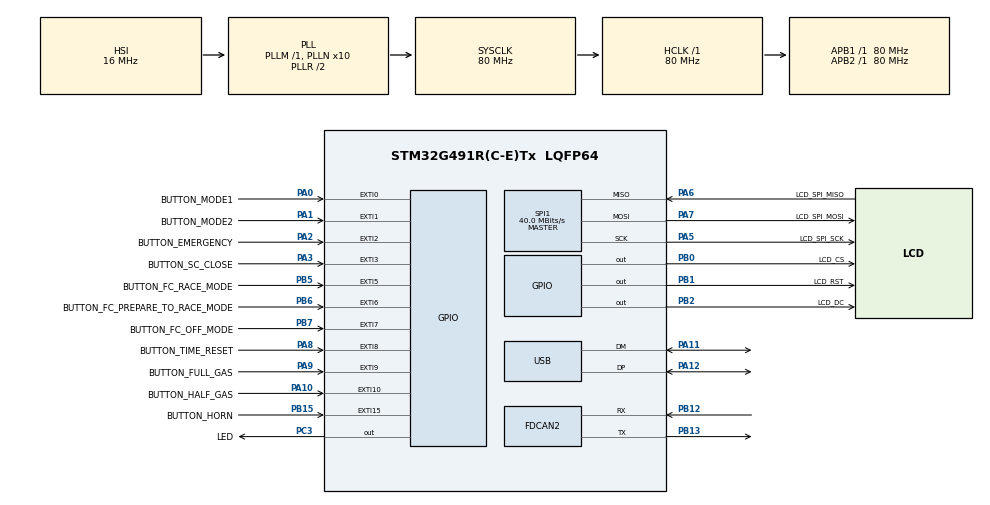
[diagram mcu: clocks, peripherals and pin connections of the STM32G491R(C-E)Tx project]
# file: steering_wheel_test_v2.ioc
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Dma.Request0=SPI1_TX
Dma.SPI1_TX.0.Direction=DMA_MEMORY_TO_PERIPH
Dma.SPI1_TX.0.EventEnable=DISABLE
Dma.SPI1_TX.0.Instance=DMA1_Channel3
Dma.SPI1_TX.0.MemDataAlignment=DMA_MDATAALIGN_BYTE
Dma.SPI1_TX.0.MemInc=DMA_MINC_ENABLE
Dma.SPI1_TX.0.Mode=DMA_NORMAL
Dma.SPI1_TX.0.PeriphDataAlignment=DMA_PDATAALIGN_BYTE
Dma.SPI1_TX.0.PeriphInc=DMA_PINC_DISABLE
Dma.SPI1_TX.0.Polarity=HAL_DMAMUX_REQ_GEN_RISING
Dma.SPI1_TX.0.Priority=DMA_PRIORITY_LOW
Dma.SPI1_TX.0.RequestNumber=1
Dma.SPI1_TX.0.SignalID=NONE
Dma.SPI1_TX.0.SyncEnable=DISABLE
Dma.SPI1_TX.0.SyncPolarity=HAL_DMAMUX_SYNC_NO_EVENT
Dma.SPI1_TX.0.SyncRequestNumber=1
Dma.SPI1_TX.0.SyncSignalID=NONE
FDCAN2.AutoRetransmission=ENABLE
FDCAN2.CalculateBaudRateNominal=500000
FDCAN2.CalculateTimeBitNominal=2000
FDCAN2.CalculateTimeQuantumNominal=400.0
FDCAN2.NominalPrescaler=32
FDCAN2.StdFiltersNbr=3
Mcu.Family=STM32G4
Mcu.Name=STM32G491R(C-E)Tx
Mcu.Package=LQFP64
NVIC.DMA1_Channel3_IRQn=true\:0\:0\:false\:false\:true\:false\:true\:true
NVIC.EXTI0_IRQn=true\:0\:0\:false\:false\:true\:true\:true\:true
NVIC.EXTI15_10_IRQn=true\:0\:0\:false\:false\:true\:true\:true\:true
NVIC.EXTI1_IRQn=true\:0\:0\:false\:false\:true\:true\:true\:true
NVIC.EXTI2_IRQn=true\:0\:0\:false\:false\:true\:true\:true\:true
NVIC.EXTI3_IRQn=true\:0\:0\:false\:false\:true\:true\:true\:true
NVIC.EXTI9_5_IRQn=true\:0\:0\:false\:false\:true\:true\:true\:true
NVIC.PriorityGroup=NVIC_PRIORITYGROUP_4
NVIC.SPI1_IRQn=true\:0\:0\:false\:false\:true\:true\:true\:true
NVIC.TIM6_DAC_IRQn=true\:0\:0\:false\:false\:true\:true\:true\:true
PA0.GPIO_Label=BUTTON_MODE1
PA0.GPIO_ModeDefaultEXTI=GPIO_MODE_IT_RISING_FALLING
PA0.GPIO_PuPd=GPIO_PULLUP
PA0.Signal=GPXTI0
PA1.GPIO_Label=BUTTON_MODE2
PA1.GPIO_ModeDefaultEXTI=GPIO_MODE_IT_RISING_FALLING
PA1.GPIO_PuPd=GPIO_PULLUP
PA1.Signal=GPXTI1
PA10.GPIO_Label=BUTTON_HALF_GAS
PA10.GPIO_ModeDefaultEXTI=GPIO_MODE_IT_RISING_FALLING
PA10.GPIO_PuPd=GPIO_PULLUP
PA10.Signal=GPXTI10
PA11.Mode=Device
PA11.Signal=USB_DM
PA12.Mode=Device
PA12.Signal=USB_DP
PA13.GPIO_Label=T_SWDIO
PA13.Mode=Trace_Asynchronous_SW
PA13.Signal=SYS_JTMS-SWDIO
PA14.GPIO_Label=T_SWCLK
PA14.Mode=Trace_Asynchronous_SW
PA14.Signal=SYS_JTCK-SWCLK
PA2.GPIO_Label=BUTTON_EMERGENCY
PA2.GPIO_ModeDefaultEXTI=GPIO_MODE_IT_RISING_FALLING
PA2.GPIO_PuPd=GPIO_PULLUP
PA2.Signal=GPXTI2
PA3.GPIO_Label=BUTTON_SC_CLOSE
PA3.GPIO_ModeDefaultEXTI=GPIO_MODE_IT_RISING_FALLING
PA3.GPIO_PuPd=GPIO_PULLUP
PA3.Signal=GPXTI3
PA5.GPIO_Label=LCD_SPI_SCK
PA5.GPIO_Speed=GPIO_SPEED_FREQ_VERY_HIGH
PA5.Mode=Full_Duplex_Master
PA5.Signal=SPI1_SCK
PA6.GPIO_Label=LCD_SPI_MISO
PA6.GPIO_Speed=GPIO_SPEED_FREQ_VERY_HIGH
PA6.Mode=Full_Duplex_Master
PA6.Signal=SPI1_MISO
PA7.GPIO_Label=LCD_SPI_MOSI
PA7.GPIO_Speed=GPIO_SPEED_FREQ_VERY_HIGH
PA7.Mode=Full_Duplex_Master
PA7.Signal=SPI1_MOSI
PA8.GPIO_Label=BUTTON_TIME_RESET
PA8.GPIO_ModeDefaultEXTI=GPIO_MODE_IT_RISING_FALLING
PA8.GPIO_PuPd=GPIO_PULLUP
PA8.Signal=GPXTI8
PA9.GPIO_Label=BUTTON_FULL_GAS
PA9.GPIO_ModeDefaultEXTI=GPIO_MODE_IT_RISING_FALLING
PA9.GPIO_PuPd=GPIO_PULLUP
PA9.Signal=GPXTI9
PB0.GPIO_Label=LCD_CS
PB0.Signal=GPIO_Output
PB1.GPIO_Label=LCD_RST
PB1.Signal=GPIO_Output
PB12.Mode=FDCAN_Activate
PB12.Signal=FDCAN2_RX
PB13.Mode=FDCAN_Activate
PB13.Signal=FDCAN2_TX
PB15.GPIO_Label=BUTTON_HORN
PB15.GPIO_ModeDefaultEXTI=GPIO_MODE_IT_RISING_FALLING
PB15.GPIO_PuPd=GPIO_PULLUP
PB15.Signal=GPXTI15
PB2.GPIO_Label=LCD_DC
PB2.Signal=GPIO_Output
PB3.GPIO_Label=T_SWO
PB3.Mode=Trace_Asynchronous_SW
PB3.Signal=SYS_JTDO-SWO
PB5.GPIO_Label=BUTTON_FC_RACE_MODE
PB5.GPIO_ModeDefaultEXTI=GPIO_MODE_IT_RISING_FALLING
PB5.GPIO_PuPd=GPIO_PULLUP
PB5.Signal=GPXTI5
PB6.GPIO_Label=BUTTON_FC_PREPARE_TO_RACE_MODE
PB6.GPIO_ModeDefaultEXTI=GPIO_MODE_IT_RISING_FALLING
PB6.GPIO_PuPd=GPIO_PULLUP
PB6.Signal=GPXTI6
PB7.GPIO_Label=BUTTON_FC_OFF_MODE
PB7.GPIO_ModeDefaultEXTI=GPIO_MODE_IT_RISING_FALLING
PB7.GPIO_PuPd=GPIO_PULLUP
PB7.Signal=GPXTI7
PC14-OSC32_IN.GPIO_Label=RCC_OSC32_IN
PC14-OSC32_IN.Signal=RCC_OSC32_IN
PC15-OSC32_OUT.GPIO_Label=RCC_OSC32_OUT
PC15-OSC32_OUT.Signal=RCC_OSC32_OUT
PC3.GPIO_Label=LED
PC3.Signal=GPIO_Output
PF0-OSC_IN.GPIO_Label=RCC_OSC_IN
PF0-OSC_IN.Signal=RCC_OSC_IN
PF1-OSC_OUT.GPIO_Label=RCC_OSC_OUT
PF1-OSC_OUT.Signal=RCC_OSC_OUT
ProjectManager.HeapSize=0x200
ProjectManager.StackSize=0x400
ProjectManager.TargetToolchain=CMake
RCC.ADC12Freq_Value=80000000
RCC.ADC345Freq_Value=80000000
RCC.AHBFreq_Value=80000000
RCC.APB1Freq_Value=80000000
RCC.APB1TimFreq_Value=80000000
RCC.APB2Freq_Value=80000000
RCC.APB2TimFreq_Value=80000000
RCC.CortexFreq_Value=80000000
RCC.EXTERNAL_CLOCK_VALUE=12288000
RCC.HCLKFreq_Value=80000000
RCC.HSE_VALUE=24000000
RCC.HSI48_VALUE=48000000
RCC.HSI_VALUE=16000000
RCC.LSE_VALUE=32768
RCC.PLLN=10
RCC.RTCClockSelection=RCC_RTCCLKSOURCE_LSE
RCC.SYSCLKFreq_VALUE=80000000
RCC.SYSCLKSource=RCC_SYSCLKSOURCE_PLLCLK
RCC.USBFreq_Value=48000000
RCC.VCOOutputFreq_Value=160000000
SPI1.CalculateBaudRate=40.0 MBits/s
SPI1.DataSize=SPI_DATASIZE_8BIT
SPI1.Direction=SPI_DIRECTION_2LINES
SPI1.Mode=SPI_MODE_MASTER
SPI1.VirtualType=VM_MASTER
TIM6.PeriodNoDither=100-1
TIM6.Prescaler=8000-1
VP_SYS_VS_DBSignals.Mode=DisableDeadBatterySignals
VP_TIM6_VS_ClockSourceINT.Mode=Enable_Timer
board=NUCLEO-G491RE

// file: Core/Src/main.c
/* USER CODE BEGIN Header */
/**
  ******************************************************************************
  * @file           : main.c
  * @brief          : Main program body
  ******************************************************************************
  * @attention
  *
  * Copyright (c) 2025 STMicroelectronics.
  * All rights reserved.
  *
  * This software is licensed under terms that can be found in the LICENSE file
  * in the root directory of this software component.
  * If no LICENSE file comes with this software, it is provided AS-IS.
  *
  ******************************************************************************
  */
/* USER CODE END Header */
#include "main.h"
#include "dma.h"
#include "fdcan.h"
#include "spi.h"
#include "tim.h"
#include "usb.h"
#include "gpio.h"

/* USER CODE BEGIN Includes */
#include "lvgl.h"
#include "lcd_controller.h"
#include "button.h"
#include "can_controller.h"
#include "ui.h"
#include "screens.h"
#include "steering_wheel.h"
/* USER CODE END Includes */

/* USER CODE BEGIN PV */
extern lv_meter_indicator_t* indicator1;
/* USER CODE END PV */

void SystemClock_Config(void);

int main(void)
{

  /* MCU Configuration--------------------------------------------------------*/

  /* Reset of all peripherals, Initializes the Flash interface and the Systick. */
  HAL_Init();

  /* Configure the system clock */
  SystemClock_Config();

  /* Initialize all configured peripherals */
  MX_GPIO_Init();
  MX_DMA_Init();
  MX_FDCAN2_Init();
  MX_USB_PCD_Init();
  MX_SPI1_Init();
  MX_TIM6_Init();
  /* USER CODE BEGIN 2 */
  steering_wheel_init();
  /* USER CODE END 2 */

  /* Infinite loop */
  /* USER CODE BEGIN WHILE */
  while (1)
  {
    steering_wheel_loop();
    HAL_Delay(5);
    /* USER CODE END WHILE */

  }
}

void SystemClock_Config(void)
{
  RCC_OscInitTypeDef RCC_OscInitStruct = {0};
  RCC_ClkInitTypeDef RCC_ClkInitStruct = {0};

  /** Configure the main internal regulator output voltage
  */
  HAL_PWREx_ControlVoltageScaling(PWR_REGULATOR_VOLTAGE_SCALE1);

  /** Initializes the RCC Oscillators according to the specified parameters
  * in the RCC_OscInitTypeDef structure.
  */
  RCC_OscInitStruct.OscillatorType = RCC_OSCILLATORTYPE_HSI|RCC_OSCILLATORTYPE_HSI48;
  RCC_OscInitStruct.HSIState = RCC_HSI_ON;
  RCC_OscInitStruct.HSICalibrationValue = RCC_HSICALIBRATION_DEFAULT;
  RCC_OscInitStruct.HSI48State = RCC_HSI48_ON;
  RCC_OscInitStruct.PLL.PLLState = RCC_PLL_ON;
  RCC_OscInitStruct.PLL.PLLSource = RCC_PLLSOURCE_HSI;
  RCC_OscInitStruct.PLL.PLLM = RCC_PLLM_DIV1;
  RCC_OscInitStruct.PLL.PLLN = 10;
  RCC_OscInitStruct.PLL.PLLP = RCC_PLLP_DIV2;
  RCC_OscInitStruct.PLL.PLLQ = RCC_PLLQ_DIV2;
  RCC_OscInitStruct.PLL.PLLR = RCC_PLLR_DIV2;
  if (HAL_RCC_OscConfig(&RCC_OscInitStruct) != HAL_OK)
  {
    Error_Handler();
  }

  /** Initializes the CPU, AHB and APB buses clocks
  */
  RCC_ClkInitStruct.ClockType = RCC_CLOCKTYPE_HCLK|RCC_CLOCKTYPE_SYSCLK
                              |RCC_CLOCKTYPE_PCLK1|RCC_CLOCKTYPE_PCLK2;
  RCC_ClkInitStruct.SYSCLKSource = RCC_SYSCLKSOURCE_PLLCLK;
  RCC_ClkInitStruct.AHBCLKDivider = RCC_SYSCLK_DIV1;
  RCC_ClkInitStruct.APB1CLKDivider = RCC_HCLK_DIV1;
  RCC_ClkInitStruct.APB2CLKDivider = RCC_HCLK_DIV1;

  if (HAL_RCC_ClockConfig(&RCC_ClkInitStruct, FLASH_LATENCY_2) != HAL_OK)
  {
    Error_Handler();
  }
}

void Error_Handler(void)
{
  __disable_irq();
  while (1)
  {
  }
}
